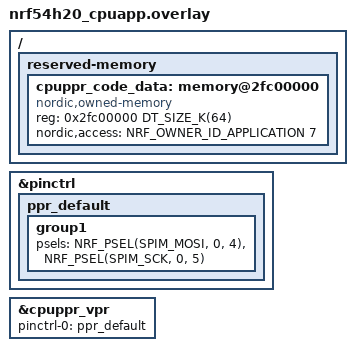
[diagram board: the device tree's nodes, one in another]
/*
 * Copyright (c) 2025 Nordic Semiconductor ASA
 *
 * SPDX-License-Identifier: LicenseRef-Nordic-5-Clause
 */

/* Remove IPC to PPR and reconfigure PPR memory */
/delete-node/ &{/ipc/ipc-2-13};
/delete-node/ &cpuppr_code_data;
/{
	reserved-memory {

		cpuppr_code_data: memory@2fc00000 {
			compatible = "nordic,owned-memory";
			reg = <0x2fc00000 DT_SIZE_K(64)>;
			status = "okay";
			nordic,access = <NRF_OWNER_ID_APPLICATION 7>;
			#address-cells = <1>;
			#size-cells = <1>;
			ranges = <0x0 0x2fc00000 0x10000>;
		};
	};
};

&pinctrl {
	ppr_default: ppr_default {
		group1 {
			psels = <NRF_PSEL(SPIM_MOSI, 0, 4)>,
				<NRF_PSEL(SPIM_SCK, 0, 5)>;
		};
	};
};

&cpuppr_vpr {
	status = "okay";
	pinctrl-0 = <&ppr_default>;
	pinctrl-names = "default";
};
